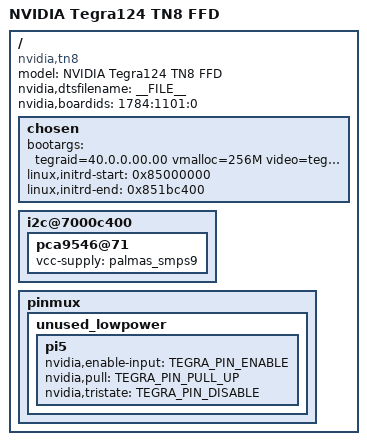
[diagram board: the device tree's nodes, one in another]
/dts-v1/;

#include "tegra124.dtsi"
#include "tegra124-platforms/tegra124-tn8-io.dtsi"
#include "tegra124-platforms/tegra124-tn8-p1761-emc-2gb.dtsi"
#include "tegra124-platforms/tegra124-e1780-powermon.dtsi"
#include "tegra124-platforms/tegra124-tn8-e1936-pmic.dtsi"
#include "tegra124-platforms/tegra124-tn8-e1936-fixed.dtsi"
#include "tegra124-platforms/tegra124-tn8-sensors.dtsi"
#include "tegra124-platforms/tegra124-p1761-pinmux.dtsi"
#include "tegra124-platforms/tegra124-p1761-gpio-default.dtsi"
#include "tegra124-platforms/tegra124-e1780-keys.dtsi"

/ {
	model = "NVIDIA Tegra124 TN8 FFD";
	compatible = "nvidia,tn8", "nvidia,tegra124";
	nvidia,dtsfilename = __FILE__;
	nvidia,boardids = "1784:1101:0";
	#address-cells = <1>;
	#size-cells = <1>;

	chosen {
		bootargs = "tegraid=40.0.0.00.00 vmalloc=256M video=tegrafb console=ttyS0,115200n8 earlyprintk";
		linux,initrd-start = <0x85000000>;
		linux,initrd-end = <0x851bc400>;
	};
	i2c@7000c400 {
		pca9546@71 {
			vcc-supply = <&palmas_smps9>;
		};
	};

	pinmux {
		unused_lowpower {
			pi5 {
				nvidia,enable-input = <TEGRA_PIN_ENABLE>;
				nvidia,pull = <TEGRA_PIN_PULL_UP>;
				nvidia,tristate = <TEGRA_PIN_DISABLE>;
			};
		};
	};
};

